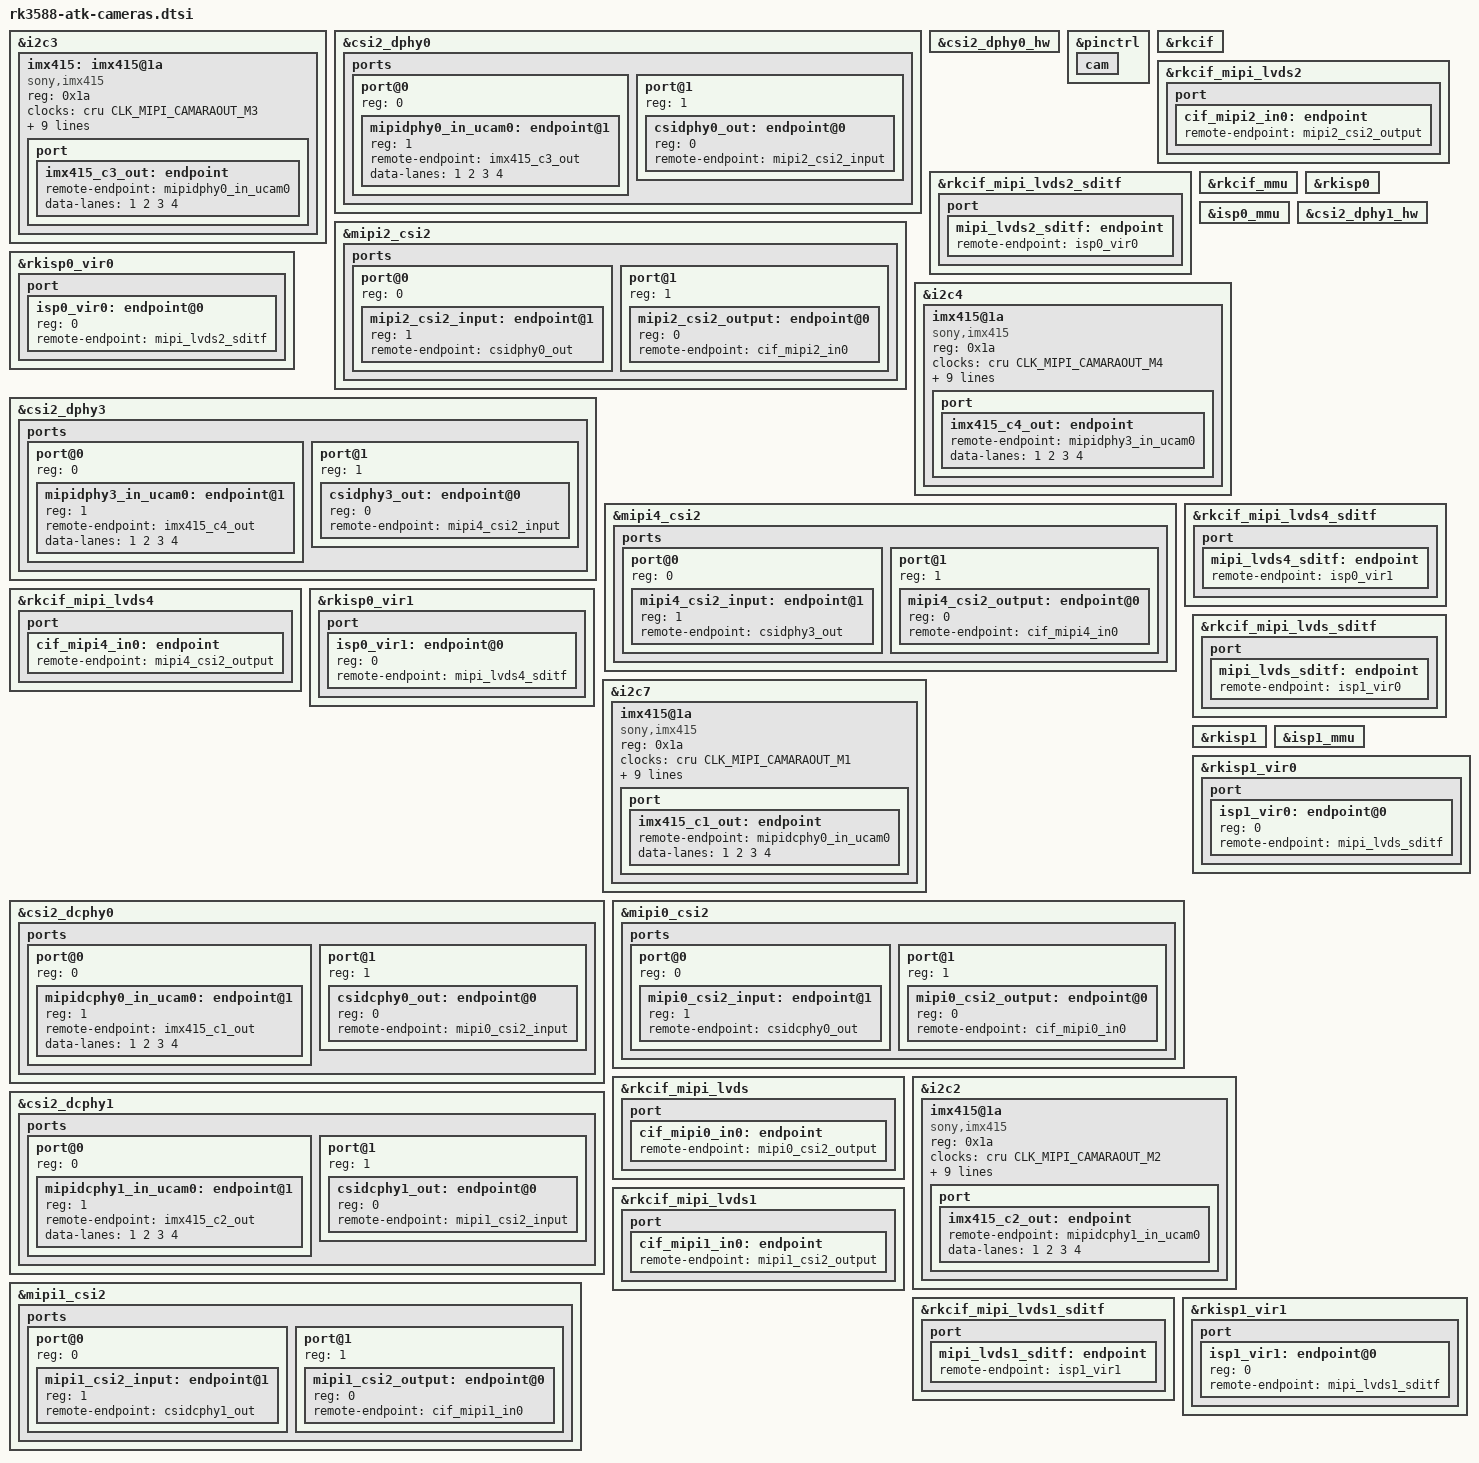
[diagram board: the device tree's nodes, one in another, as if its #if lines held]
// SPDX-License-Identifier: (GPL-2.0+ OR MIT)
/*
 * Copyright (c) 2022 Rockchip Electronics Co., Ltd.
 *
 */

#define ATK_CAMERA_1	//MIPI CSI1
//#define ATK_CAMERA_2	//MIPI CSI2
#define ATK_CAMERA_3	//MIPI CSI3
//#define ATK_CAMERA_4	//MIPI CSI4

/ {
};

#if defined(ATK_CAMERA_3)
&i2c3 {
	status = "okay";

	imx415: imx415@1a {
		compatible = "sony,imx415";
		reg = <0x1a>;
		clocks = <&cru CLK_MIPI_CAMARAOUT_M3>;
		clock-names = "xvclk";
		pinctrl-names = "default";
		pinctrl-0 = <&mipim0_camera3_clk>;
		power-domains = <&power RK3588_PD_VI>;
		reset-gpios = <&gpio1 RK_PB1 GPIO_ACTIVE_LOW>;
		power-gpios = <&gpio1 RK_PA7 GPIO_ACTIVE_HIGH>;
		//pwdn-gpios = <&gpio1 RK_PA7 GPIO_ACTIVE_HIGH>;
		rockchip,camera-module-index = <0>;
		rockchip,camera-module-facing = "back";
		rockchip,camera-module-name = "CMK-OT2022-PX1";
		rockchip,camera-module-lens-name = "IR0147-50IRC-8M-F20";
		port {
			imx415_c3_out: endpoint {
				remote-endpoint = <&mipidphy0_in_ucam0>;
				data-lanes = <1 2 3 4>;
			};
		};
	};
};

&csi2_dphy0 {
	status = "okay";

	ports {
		#address-cells = <1>;
		#size-cells = <0>;
		port@0 {
			reg = <0>;
			#address-cells = <1>;
			#size-cells = <0>;

			mipidphy0_in_ucam0: endpoint@1 {
				reg = <1>;
				remote-endpoint = <&imx415_c3_out>;
				data-lanes = <1 2 3 4>;
			};
		};
		port@1 {
			reg = <1>;
			#address-cells = <1>;
			#size-cells = <0>;

			csidphy0_out: endpoint@0 {
				reg = <0>;
				remote-endpoint = <&mipi2_csi2_input>;
			};
		};
	};
};

&csi2_dphy0_hw {
	status = "okay";
};

&mipi2_csi2 {
	status = "okay";

	ports {
		#address-cells = <1>;
		#size-cells = <0>;

		port@0 {
			reg = <0>;
			#address-cells = <1>;
			#size-cells = <0>;

			mipi2_csi2_input: endpoint@1 {
				reg = <1>;
				remote-endpoint = <&csidphy0_out>;
			};
		};

		port@1 {
			reg = <1>;
			#address-cells = <1>;
			#size-cells = <0>;

			mipi2_csi2_output: endpoint@0 {
				reg = <0>;
				remote-endpoint = <&cif_mipi2_in0>;
			};
		};
	};
};

&pinctrl {
	cam {
	};
};

&rkcif {
	status = "okay";
};

&rkcif_mipi_lvds2 {
	status = "okay";

	port {
		cif_mipi2_in0: endpoint {
			remote-endpoint = <&mipi2_csi2_output>;
		};
	};
};

&rkcif_mipi_lvds2_sditf {
	status = "okay";

	port {
		mipi_lvds2_sditf: endpoint {
			remote-endpoint = <&isp0_vir0>;
		};
	};
};

&rkcif_mmu {
	status = "okay";
};

&rkisp0 {
	status = "okay";
};

&isp0_mmu {
	status = "okay";
};

&rkisp0_vir0 {
	status = "okay";

	port {
		#address-cells = <1>;
		#size-cells = <0>;

		isp0_vir0: endpoint@0 {
			reg = <0>;
			remote-endpoint = <&mipi_lvds2_sditf>;
		};
	};
};
#endif


#if defined(ATK_CAMERA_4)
&i2c4 {
	imx415@1a {
		compatible = "sony,imx415";
		reg = <0x1a>;
		clocks = <&cru CLK_MIPI_CAMARAOUT_M4>;
		clock-names = "xvclk";
		pinctrl-names = "default";
		pinctrl-0 = <&mipim0_camera4_clk>;
		power-domains = <&power RK3588_PD_VI>;
		reset-gpios = <&gpio1 RK_PB2 GPIO_ACTIVE_LOW>;
		power-gpios = <&gpio1 RK_PB0 GPIO_ACTIVE_HIGH>;
		rockchip,camera-module-index = <1>;
		rockchip,camera-module-facing = "back";
		rockchip,camera-module-name = "CMK-OT2022-PX1";
		rockchip,camera-module-lens-name = "IR0147-50IRC-8M-F20";
		port {
			imx415_c4_out: endpoint {
				remote-endpoint = <&mipidphy3_in_ucam0>;
				data-lanes = <1 2 3 4>;
			};
		};
	};
};

&csi2_dphy3 {
	status = "okay";

	ports {
		#address-cells = <1>;
		#size-cells = <0>;
		port@0 {
			reg = <0>;
			#address-cells = <1>;
			#size-cells = <0>;

			mipidphy3_in_ucam0: endpoint@1 {
				reg = <1>;
				remote-endpoint = <&imx415_c4_out>;
				data-lanes = <1 2 3 4>;
			};
		};
		port@1 {
			reg = <1>;
			#address-cells = <1>;
			#size-cells = <0>;

			csidphy3_out: endpoint@0 {
				reg = <0>;
				remote-endpoint = <&mipi4_csi2_input>;
			};
		};
	};
};

&csi2_dphy1_hw {
	status = "okay";
};

&mipi4_csi2 {
	status = "okay";

	ports {
		#address-cells = <1>;
		#size-cells = <0>;

		port@0 {
			reg = <0>;
			#address-cells = <1>;
			#size-cells = <0>;

			mipi4_csi2_input: endpoint@1 {
				reg = <1>;
				remote-endpoint = <&csidphy3_out>;
			};
		};

		port@1 {
			reg = <1>;
			#address-cells = <1>;
			#size-cells = <0>;

			mipi4_csi2_output: endpoint@0 {
				reg = <0>;
				remote-endpoint = <&cif_mipi4_in0>;
			};
		};
	};
};

&rkcif {
	status = "okay";
};

&rkcif_mipi_lvds4 {
	status = "okay";

	port {
		cif_mipi4_in0: endpoint {
			remote-endpoint = <&mipi4_csi2_output>;
		};
	};
};

&rkcif_mipi_lvds4_sditf {
	status = "okay";

	port {
		mipi_lvds4_sditf: endpoint {
			remote-endpoint = <&isp0_vir1>;
		};
	};
};

&rkcif_mmu {
	status = "okay";
};

&rkisp0 {
	status = "okay";
};

&isp0_mmu {
	status = "okay";
};

&rkisp0_vir1 {
	status = "okay";

	port {
		#address-cells = <1>;
		#size-cells = <0>;

		isp0_vir1: endpoint@0 {
			reg = <0>;
			remote-endpoint = <&mipi_lvds4_sditf>;
		};
	};
};
#endif


#if defined(ATK_CAMERA_1)
&i2c7 {
	imx415@1a {
		compatible = "sony,imx415";
		reg = <0x1a>;
		clocks = <&cru CLK_MIPI_CAMARAOUT_M1>;
		clock-names = "xvclk";
		pinctrl-names = "default";
		pinctrl-0 = <&mipim0_camera1_clk>;
		power-domains = <&power RK3588_PD_VI>;
		reset-gpios = <&gpio1 RK_PD2 GPIO_ACTIVE_LOW>;
		power-gpios = <&gpio1 RK_PA2 GPIO_ACTIVE_HIGH>;
		rockchip,camera-module-index = <2>;
		rockchip,camera-module-facing = "back";
		rockchip,camera-module-name = "CMK-OT2022-PX1";
		rockchip,camera-module-lens-name = "IR0147-50IRC-8M-F20";
		port {
			imx415_c1_out: endpoint {
				remote-endpoint = <&mipidcphy0_in_ucam0>;
				data-lanes = <1 2 3 4>;
			};
		};
	};
};

&csi2_dcphy0 {
	status = "okay";

	ports {
		#address-cells = <1>;
		#size-cells = <0>;
		port@0 {
			reg = <0>;
			#address-cells = <1>;
			#size-cells = <0>;

			mipidcphy0_in_ucam0: endpoint@1 {
				reg = <1>;
				remote-endpoint = <&imx415_c1_out>;
				data-lanes = <1 2 3 4>;
			};
		};
		port@1 {
			reg = <1>;
			#address-cells = <1>;
			#size-cells = <0>;

			csidcphy0_out: endpoint@0 {
				reg = <0>;
				remote-endpoint = <&mipi0_csi2_input>;
			};
		};
	};
};

&mipi0_csi2 {
	status = "okay";

	ports {
		#address-cells = <1>;
		#size-cells = <0>;

		port@0 {
			reg = <0>;
			#address-cells = <1>;
			#size-cells = <0>;

			mipi0_csi2_input: endpoint@1 {
				reg = <1>;
				remote-endpoint = <&csidcphy0_out>;
			};
		};

		port@1 {
			reg = <1>;
			#address-cells = <1>;
			#size-cells = <0>;

			mipi0_csi2_output: endpoint@0 {
				reg = <0>;
				remote-endpoint = <&cif_mipi0_in0>;
			};
		};
	};
};

&rkcif {
	status = "okay";
};

&rkcif_mipi_lvds {
	status = "okay";

	port {
		cif_mipi0_in0: endpoint {
			remote-endpoint = <&mipi0_csi2_output>;
		};
	};
};

&rkcif_mipi_lvds_sditf {
	status = "okay";

	port {
		mipi_lvds_sditf: endpoint {
			remote-endpoint = <&isp1_vir0>;
		};
	};
};

&rkcif_mmu {
	status = "okay";
};

&rkisp1 {
	status = "okay";
};

&isp1_mmu {
	status = "okay";
};

&rkisp1_vir0 {
	status = "okay";

	port {
		#address-cells = <1>;
		#size-cells = <0>;

		isp1_vir0: endpoint@0 {
			reg = <0>;
			remote-endpoint = <&mipi_lvds_sditf>;
		};
	};
};
#endif


#if defined(ATK_CAMERA_2)
&i2c2 {
	imx415@1a {
		compatible = "sony,imx415";
		reg = <0x1a>;
		clocks = <&cru CLK_MIPI_CAMARAOUT_M2>;
		clock-names = "xvclk";
		pinctrl-names = "default";
		pinctrl-0 = <&mipim0_camera2_clk>;
		power-domains = <&power RK3588_PD_VI>;
		reset-gpios = <&gpio1 RK_PD3 GPIO_ACTIVE_LOW>;
		power-gpios = <&gpio1 RK_PA4 GPIO_ACTIVE_HIGH>;
		rockchip,camera-module-index = <3>;
		rockchip,camera-module-facing = "back";
		rockchip,camera-module-name = "CMK-OT2022-PX1";
		rockchip,camera-module-lens-name = "IR0147-50IRC-8M-F20";
		port {
			imx415_c2_out: endpoint {
				remote-endpoint = <&mipidcphy1_in_ucam0>;
				data-lanes = <1 2 3 4>;
			};
		};
	};
};

&csi2_dcphy1 {
	status = "okay";

	ports {
		#address-cells = <1>;
		#size-cells = <0>;
		port@0 {
			reg = <0>;
			#address-cells = <1>;
			#size-cells = <0>;

			mipidcphy1_in_ucam0: endpoint@1 {
				reg = <1>;
				remote-endpoint = <&imx415_c2_out>;
				data-lanes = <1 2 3 4>;
			};
		};
		port@1 {
			reg = <1>;
			#address-cells = <1>;
			#size-cells = <0>;

			csidcphy1_out: endpoint@0 {
				reg = <0>;
				remote-endpoint = <&mipi1_csi2_input>;
			};
		};
	};
};

&mipi1_csi2 {
	status = "okay";

	ports {
		#address-cells = <1>;
		#size-cells = <0>;

		port@0 {
			reg = <0>;
			#address-cells = <1>;
			#size-cells = <0>;

			mipi1_csi2_input: endpoint@1 {
				reg = <1>;
				remote-endpoint = <&csidcphy1_out>;
			};
		};

		port@1 {
			reg = <1>;
			#address-cells = <1>;
			#size-cells = <0>;

			mipi1_csi2_output: endpoint@0 {
				reg = <0>;
				remote-endpoint = <&cif_mipi1_in0>;
			};
		};
	};
};

&rkcif {
	status = "okay";
};

&rkcif_mipi_lvds1 {
	status = "okay";

	port {
		cif_mipi1_in0: endpoint {
			remote-endpoint = <&mipi1_csi2_output>;
		};
	};
};

&rkcif_mipi_lvds1_sditf {
	status = "okay";

	port {
		mipi_lvds1_sditf: endpoint {
			remote-endpoint = <&isp1_vir1>;
		};
	};
};

&rkcif_mmu {
	status = "okay";
};

&rkisp1 {
	status = "okay";
};

&isp1_mmu {
	status = "okay";
};

&rkisp1_vir1 {
	status = "okay";

	port {
		#address-cells = <1>;
		#size-cells = <0>;

		isp1_vir1: endpoint@0 {
			reg = <0>;
			remote-endpoint = <&mipi_lvds1_sditf>;
		};
	};
};
#endif

